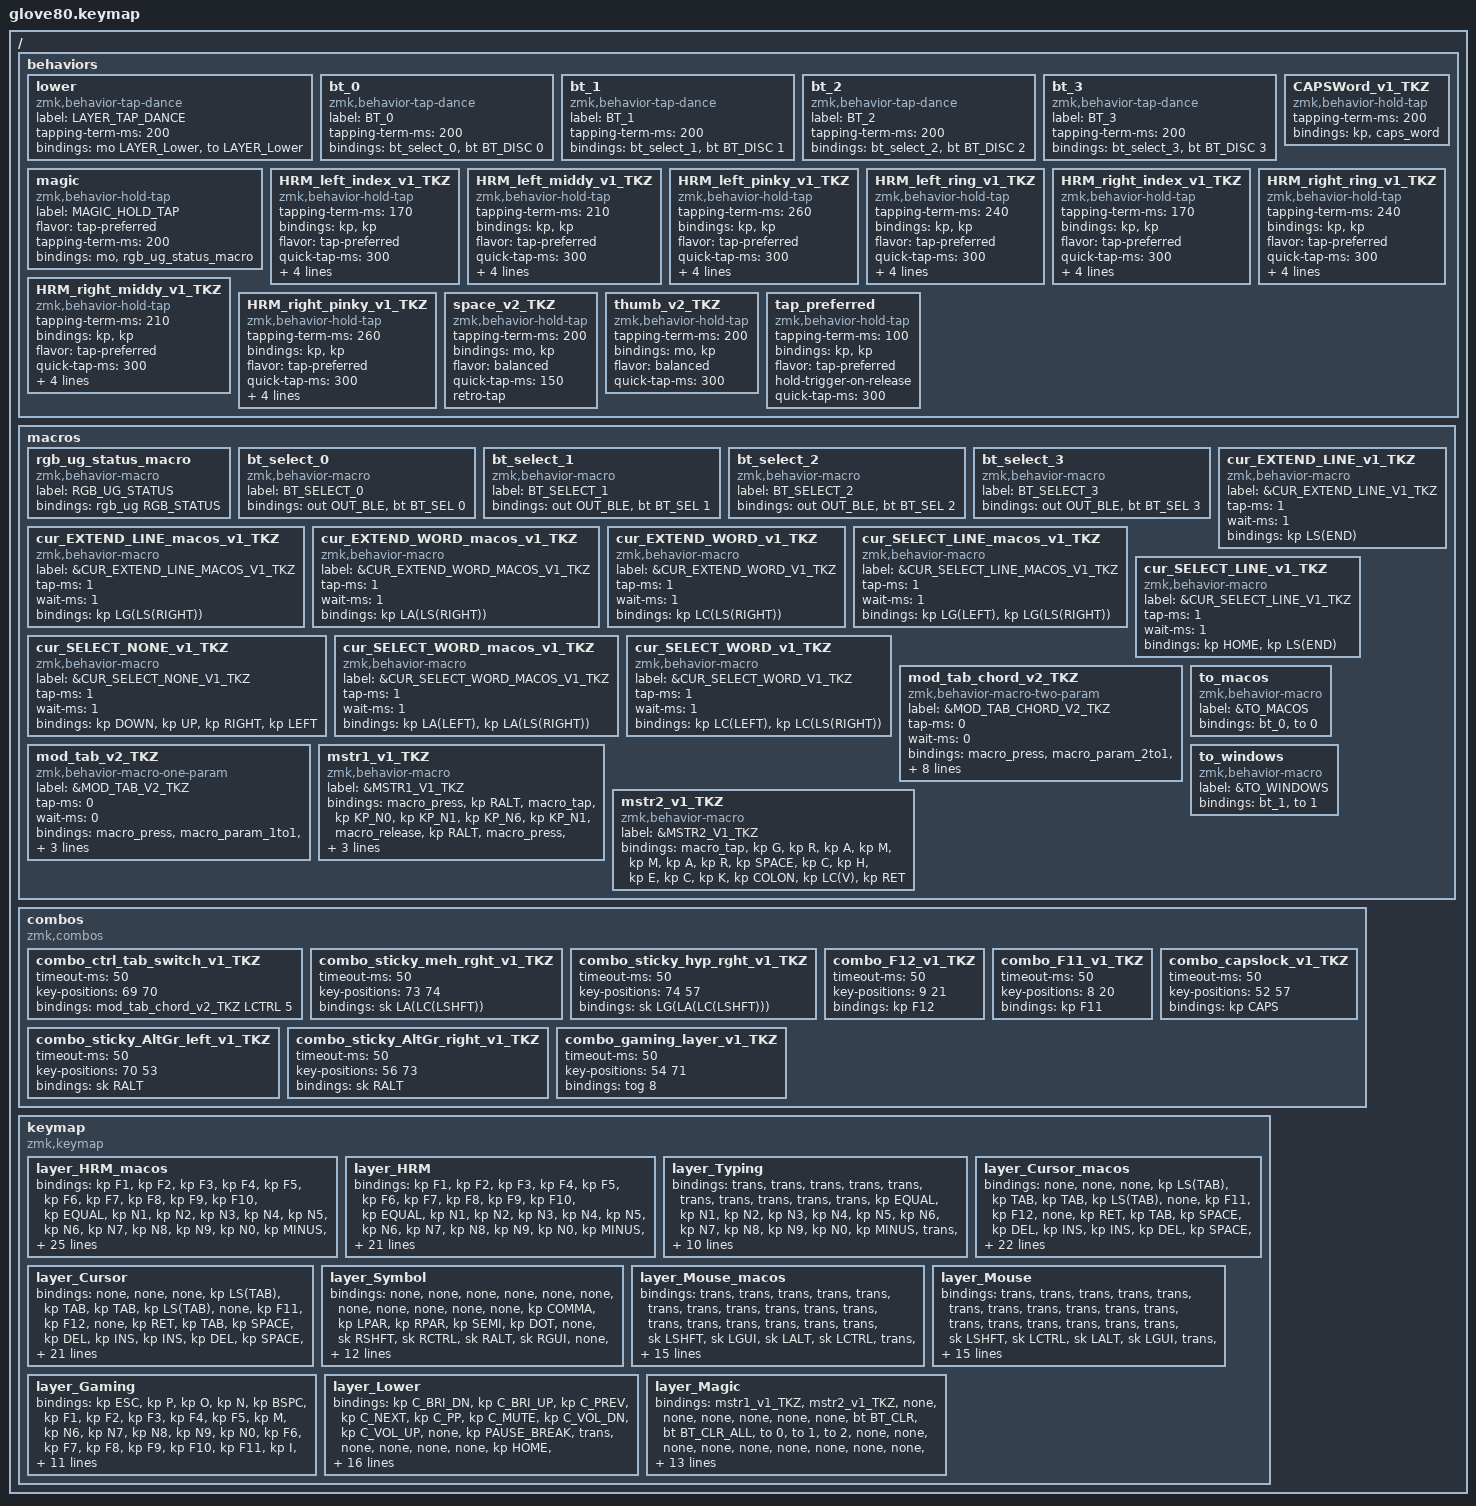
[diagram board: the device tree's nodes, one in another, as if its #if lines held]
/*
 * Copyright (c) 2020 The ZMK Contributors
 * Copyright (c) 2023 Innaworks Development Limited, trading as MoErgo
 *
 * SPDX-License-Identifier: MIT
 */
// clang-format off
/* THIS FILE WAS GENERATED BY GLOVE80 LAYOUT EDITOR
 *
 * This file was generated automatically. You may or may not want to
 * edit it directly.
 */
/* Include all behavior includes needed */
/* On demand includes */

#include <behaviors.dtsi>
#include <dt-bindings/zmk/bt.h>
#include <dt-bindings/zmk/keys.h>
#include <dt-bindings/zmk/outputs.h>
#include <dt-bindings/zmk/pointing.h>
#include <dt-bindings/zmk/rgb.h>

/* */

#define HYPER LC(LS(LG(LALT)))
#define MEH LC(LG(LALT))

/* Automatically generated layer name #define */

#define LAYER_HRM_macos 0
#define LAYER_HRM 1
#define LAYER_Typing 2
#define LAYER_Cursor_macos 3
#define LAYER_Cursor 4
#define LAYER_Symbol 5
#define LAYER_Mouse_macos 6
#define LAYER_Mouse 7
#define LAYER_Gaming 8
#define LAYER_Lower 9
#define LAYER_Magic 10

/* To deal with the situation where there is no Lower layer, to keep &lower happy */
/*#ifndef LAYER_Lower
#define LAYER_Lower 0
#endif
*/
/* Custom Device-tree */
/* Glove80 system behavior & macros */

/ {
    behaviors {
        // For the "layer" key, it'd nice to be able to use it as either a shift or a toggle.
        // Configure it as a tap dance, so the first tap (or hold) is a &mo and the second tap is a &to

        lower: lower {
            compatible = "zmk,behavior-tap-dance";
            label = "LAYER_TAP_DANCE";
            #binding-cells = <0>;
            tapping-term-ms = <200>;
            bindings = <&mo LAYER_Lower>, <&to LAYER_Lower>;
        };
    };
};

/ {
    macros {
        rgb_ug_status_macro: rgb_ug_status_macro {
            label = "RGB_UG_STATUS";
            compatible = "zmk,behavior-macro";
            #binding-cells = <0>;
            bindings = <&rgb_ug RGB_STATUS>;
        };
    };
};

/ {
    #ifdef BT_DISC_CMD

    behaviors {
        bt_0: bt_0 {
            compatible = "zmk,behavior-tap-dance";
            label = "BT_0";
            #binding-cells = <0>;
            tapping-term-ms = <200>;
            bindings = <&bt_select_0>, <&bt BT_DISC 0>;
        };

        bt_1: bt_1 {
            compatible = "zmk,behavior-tap-dance";
            label = "BT_1";
            #binding-cells = <0>;
            tapping-term-ms = <200>;
            bindings = <&bt_select_1>, <&bt BT_DISC 1>;
        };

        bt_2: bt_2 {
            compatible = "zmk,behavior-tap-dance";
            label = "BT_2";
            #binding-cells = <0>;
            tapping-term-ms = <200>;
            bindings = <&bt_select_2>, <&bt BT_DISC 2>;
        };

        bt_3: bt_3 {
            compatible = "zmk,behavior-tap-dance";
            label = "BT_3";
            #binding-cells = <0>;
            tapping-term-ms = <200>;
            bindings = <&bt_select_3>, <&bt BT_DISC 3>;
        };
    };

    macros {
        bt_select_0: bt_select_0 {
            label = "BT_SELECT_0";
            compatible = "zmk,behavior-macro";
            #binding-cells = <0>;
            bindings = <&out OUT_BLE &bt BT_SEL 0>;
        };

        bt_select_1: bt_select_1 {
            label = "BT_SELECT_1";
            compatible = "zmk,behavior-macro";
            #binding-cells = <0>;
            bindings = <&out OUT_BLE &bt BT_SEL 1>;
        };

        bt_select_2: bt_select_2 {
            label = "BT_SELECT_2";
            compatible = "zmk,behavior-macro";
            #binding-cells = <0>;
            bindings = <&out OUT_BLE &bt BT_SEL 2>;
        };

        bt_select_3: bt_select_3 {
            label = "BT_SELECT_3";
            compatible = "zmk,behavior-macro";
            #binding-cells = <0>;
            bindings = <&out OUT_BLE &bt BT_SEL 3>;
        };
    };

    #else

    macros {
        bt_0: bt_0 {
            label = "BT_0";
            compatible = "zmk,behavior-macro";
            #binding-cells = <0>;
            bindings = <&out OUT_BLE &bt BT_SEL 0>;
        };

        bt_1: bt_1 {
            label = "BT_1";
            compatible = "zmk,behavior-macro";
            #binding-cells = <0>;
            bindings = <&out OUT_BLE &bt BT_SEL 1>;
        };

        bt_2: bt_2 {
            label = "BT_2";
            compatible = "zmk,behavior-macro";
            #binding-cells = <0>;
            bindings = <&out OUT_BLE &bt BT_SEL 2>;
        };

        bt_3: bt_3 {
            label = "BT_3";
            compatible = "zmk,behavior-macro";
            #binding-cells = <0>;
            bindings = <&out OUT_BLE &bt BT_SEL 3>;
        };
    };

    #endif
};

/ {
    behaviors {
        magic: magic {
            compatible = "zmk,behavior-hold-tap";
            label = "MAGIC_HOLD_TAP";
            #binding-cells = <2>;
            flavor = "tap-preferred";
            tapping-term-ms = <200>;
            bindings = <&mo>, <&rgb_ug_status_macro>;
        };
    };
};

/* #define for key positions */

#define POS_LH_T1 52
#define POS_LH_T2 53
#define POS_LH_T3 54
#define POS_LH_T4 69
#define POS_LH_T5 70
#define POS_LH_T6 71
#define POS_LH_C1R2 15
#define POS_LH_C1R3 27
#define POS_LH_C1R4 39
#define POS_LH_C1R5 51
#define POS_LH_C2R1 4
#define POS_LH_C2R2 14
#define POS_LH_C2R3 26
#define POS_LH_C2R4 38
#define POS_LH_C2R5 50
#define POS_LH_C2R6 68
#define POS_LH_C3R1 3
#define POS_LH_C3R2 13
#define POS_LH_C3R3 25
#define POS_LH_C3R4 37
#define POS_LH_C3R5 49
#define POS_LH_C3R6 67
#define POS_LH_C4R1 2
#define POS_LH_C4R2 12
#define POS_LH_C4R3 24
#define POS_LH_C4R4 36
#define POS_LH_C4R5 48
#define POS_LH_C4R6 66
#define POS_LH_C5R1 1
#define POS_LH_C5R2 11
#define POS_LH_C5R3 23
#define POS_LH_C5R4 35
#define POS_LH_C5R5 47
#define POS_LH_C5R6 65
#define POS_LH_C6R1 0
#define POS_LH_C6R2 10
#define POS_LH_C6R3 22
#define POS_LH_C6R4 34
#define POS_LH_C6R5 46
#define POS_LH_C6R6 64
#define POS_RH_T1 57
#define POS_RH_T2 56
#define POS_RH_T3 55
#define POS_RH_T4 74
#define POS_RH_T5 73
#define POS_RH_T6 72
#define POS_RH_C1R2 16
#define POS_RH_C1R3 28
#define POS_RH_C1R4 40
#define POS_RH_C1R5 58
#define POS_RH_C2R1 5
#define POS_RH_C2R2 17
#define POS_RH_C2R3 29
#define POS_RH_C2R4 41
#define POS_RH_C2R5 59
#define POS_RH_C2R6 75
#define POS_RH_C3R1 6
#define POS_RH_C3R2 18
#define POS_RH_C3R3 30
#define POS_RH_C3R4 42
#define POS_RH_C3R5 60
#define POS_RH_C3R6 76
#define POS_RH_C4R1 7
#define POS_RH_C4R2 19
#define POS_RH_C4R3 31
#define POS_RH_C4R4 43
#define POS_RH_C4R5 61
#define POS_RH_C4R6 77
#define POS_RH_C5R1 8
#define POS_RH_C5R2 20
#define POS_RH_C5R3 32
#define POS_RH_C5R4 44
#define POS_RH_C5R5 62
#define POS_RH_C5R6 78
#define POS_RH_C6R1 9
#define POS_RH_C6R2 21
#define POS_RH_C6R3 33
#define POS_RH_C6R4 45
#define POS_RH_C6R5 63
#define POS_RH_C6R6 79

/* Custom Defined Behaviors */

/ {
};

/* Automatically generated macro definitions */

/ {
    macros {
        // Cursor Layer - Extent Line (seq) - TailorKey

        cur_EXTEND_LINE_macos_v1_TKZ: cur_EXTEND_LINE_macos_v1_TKZ {
            label = "&CUR_EXTEND_LINE_MACOS_V1_TKZ";
            compatible = "zmk,behavior-macro";
            #binding-cells = <0>;
            tap-ms = <1>;
            wait-ms = <1>;
            bindings = <&kp LG(LS(RIGHT))>;
        };

        // Cursor Layer - Extent Line (seq) - TailorKey

        cur_EXTEND_LINE_v1_TKZ: cur_EXTEND_LINE_v1_TKZ {
            label = "&CUR_EXTEND_LINE_V1_TKZ";
            compatible = "zmk,behavior-macro";
            #binding-cells = <0>;
            tap-ms = <1>;
            wait-ms = <1>;
            bindings = <&kp LS(END)>;
        };

        // Cursor Layer - Extend Word (seq) - TailorKey

        cur_EXTEND_WORD_macos_v1_TKZ: cur_EXTEND_WORD_macos_v1_TKZ {
            label = "&CUR_EXTEND_WORD_MACOS_V1_TKZ";
            compatible = "zmk,behavior-macro";
            #binding-cells = <0>;
            tap-ms = <1>;
            wait-ms = <1>;
            bindings = <&kp LA(LS(RIGHT))>;
        };

        // Cursor Layer - Extend Word (seq) - TailorKey

        cur_EXTEND_WORD_v1_TKZ: cur_EXTEND_WORD_v1_TKZ {
            label = "&CUR_EXTEND_WORD_V1_TKZ";
            compatible = "zmk,behavior-macro";
            #binding-cells = <0>;
            tap-ms = <1>;
            wait-ms = <1>;
            bindings = <&kp LC(LS(RIGHT))>;
        };

        // Cursor Layer macos - Select Line (seq) - TailorKey

        cur_SELECT_LINE_macos_v1_TKZ: cur_SELECT_LINE_macos_v1_TKZ {
            label = "&CUR_SELECT_LINE_MACOS_V1_TKZ";
            compatible = "zmk,behavior-macro";
            #binding-cells = <0>;
            tap-ms = <1>;
            wait-ms = <1>;
            bindings = <&kp LG(LEFT) &kp LG(LS(RIGHT))>;
        };

        // Cursor Layer - Select Line (seq) - TailorKey

        cur_SELECT_LINE_v1_TKZ: cur_SELECT_LINE_v1_TKZ {
            label = "&CUR_SELECT_LINE_V1_TKZ";
            compatible = "zmk,behavior-macro";
            #binding-cells = <0>;
            tap-ms = <1>;
            wait-ms = <1>;
            bindings = <&kp HOME &kp LS(END)>;
        };

        // Cursor Layer - Select None (seq) - TailorKey

        cur_SELECT_NONE_v1_TKZ: cur_SELECT_NONE_v1_TKZ {
            label = "&CUR_SELECT_NONE_V1_TKZ";
            compatible = "zmk,behavior-macro";
            #binding-cells = <0>;
            tap-ms = <1>;
            wait-ms = <1>;
            bindings = <&kp DOWN &kp UP &kp RIGHT &kp LEFT>;
        };

        // Cursor Layer - Select Word (seq) - TailorKey

        cur_SELECT_WORD_macos_v1_TKZ: cur_SELECT_WORD_macos_v1_TKZ {
            label = "&CUR_SELECT_WORD_MACOS_V1_TKZ";
            compatible = "zmk,behavior-macro";
            #binding-cells = <0>;
            tap-ms = <1>;
            wait-ms = <1>;
            bindings = <&kp LA(LEFT) &kp LA(LS(RIGHT))>;
        };

        // Cursor Layer - Select Word (seq) - TailorKey

        cur_SELECT_WORD_v1_TKZ: cur_SELECT_WORD_v1_TKZ {
            label = "&CUR_SELECT_WORD_V1_TKZ";
            compatible = "zmk,behavior-macro";
            #binding-cells = <0>;
            tap-ms = <1>;
            wait-ms = <1>;
            bindings = <&kp LC(LEFT) &kp LC(LS(RIGHT))>;
        };

        // mod_tab_switcher_chord -  TailorKey

        mod_tab_chord_v2_TKZ: mod_tab_chord_v2_TKZ {
            label = "&MOD_TAB_CHORD_V2_TKZ";
            compatible = "zmk,behavior-macro-two-param";
            #binding-cells = <2>;
            tap-ms = <0>;
            wait-ms = <0>;
            bindings =
                <&macro_press>,
                <&macro_param_2to1 &mo MACRO_PLACEHOLDER>,
                <&macro_press>,
                <&macro_param_1to1 &mod_tab_v2_TKZ MACRO_PLACEHOLDER>,
                <&macro_pause_for_release>,
                <&macro_release>,
                <&macro_param_1to1 &mod_tab_v2_TKZ MACRO_PLACEHOLDER>,
                <&macro_release>,
                <&macro_param_2to1 &mo MACRO_PLACEHOLDER>;
        };

        // mod_tab_switcher - TailorKey
        // 
        // 

        mod_tab_v2_TKZ: mod_tab_v2_TKZ {
            label = "&MOD_TAB_V2_TKZ";
            compatible = "zmk,behavior-macro-one-param";
            #binding-cells = <1>;
            tap-ms = <0>;
            wait-ms = <0>;
            bindings =
                <&macro_press>,
                <&macro_param_1to1 &kp MACRO_PLACEHOLDER>,
                <&macro_tap>,
                <&kp TAB>,
                <&macro_pause_for_release>,
                <&macro_release>,
                <&macro_param_1to1 &kp MACRO_PLACEHOLDER>;
        };

        // macro string1 sample - Magic Layer F1 - Text output sample macro 1 "¡Hola!" - TailorKey

        mstr1_v1_TKZ: mstr1_v1_TKZ {
            label = "&MSTR1_V1_TKZ";
            compatible = "zmk,behavior-macro";
            #binding-cells = <0>;
            bindings =
                <&macro_press>,
                <&kp RALT>,
                <&macro_tap>,
                <&kp KP_N0 &kp KP_N1 &kp KP_N6 &kp KP_N1>,
                <&macro_release>,
                <&kp RALT>,
                <&macro_press>,
                <&kp LSHFT>,
                <&macro_tap>,
                <&kp H>,
                <&macro_release>,
                <&kp LSHFT>,
                <&macro_tap>,
                <&kp O &kp L &kp A &kp EXCL &kp SPACE &kp RET>;
        };

        // macro string2 sample - Magic Layer F2 - Text output sample macro 2 "grammar check: <paste>" - TailorKey

        mstr2_v1_TKZ: mstr2_v1_TKZ {
            label = "&MSTR2_V1_TKZ";
            compatible = "zmk,behavior-macro";
            #binding-cells = <0>;
            bindings =
                <&macro_tap>,
                <&kp G &kp R &kp A &kp M &kp M &kp A &kp R &kp SPACE &kp C &kp H &kp E &kp C &kp K &kp COLON &kp LC(V) &kp RET>;
        };

        // macos keybinds and bt

        to_macos: to_macos {
            label = "&TO_MACOS";
            compatible = "zmk,behavior-macro";
            #binding-cells = <0>;
            bindings = <&bt_0 &to 0>;
        };

        // windows keybinds and bt uses bt1 and layer 1

        to_windows: to_windows {
            label = "&TO_WINDOWS";
            compatible = "zmk,behavior-macro";
            #binding-cells = <0>;
            bindings = <&bt_1 &to 1>;
        };
    };
};

/* Automatically generated behavior definitions */

/ {
    behaviors {
        // Capsword helper - tap for caps_word - hold for key press

        CAPSWord_v1_TKZ: CAPSWord_v1_TKZ {
            compatible = "zmk,behavior-hold-tap";
            #binding-cells = <2>;
            tapping-term-ms = <200>;
            bindings = <&kp>, <&caps_word>;
        };

        // Homerow Mod for the left index finger - TailorKey.
        // For advanced tuning of HRM values, see: https://docs.google.com/spreadsheets/d/1ESgObQelyz4lnKlfwLYsmofLJulOMK5RdGBsopLe2o8

        HRM_left_index_v1_TKZ: HRM_left_index_v1_TKZ {
            compatible = "zmk,behavior-hold-tap";
            #binding-cells = <2>;
            tapping-term-ms = <170>;
            bindings = <&kp>, <&kp>;

            flavor = "tap-preferred";
            quick-tap-ms = <300>;
            require-prior-idle-ms = <100>;
            hold-trigger-key-positions = <57 56 55 72 73 74 5 6 7 8 16 17 18 19 20 28 29 30 31 32 40 41 42 43 44 58 59 60 61 62 75 76 77 78 9 21 33 45 63 79 52 53 54 70 71 69>;
            hold-trigger-on-release;
        };

        // Homerow Mod for the left middle finger - TailorKey

        HRM_left_middy_v1_TKZ: HRM_left_middy_v1_TKZ {
            compatible = "zmk,behavior-hold-tap";
            #binding-cells = <2>;
            tapping-term-ms = <210>;
            bindings = <&kp>, <&kp>;

            flavor = "tap-preferred";
            quick-tap-ms = <300>;
            require-prior-idle-ms = <150>;
            hold-trigger-key-positions = <57 56 55 72 73 74 5 6 7 8 16 17 18 19 20 28 29 30 31 32 40 41 42 43 44 58 59 60 61 62 75 76 77 78 9 21 33 45 63 79 52 53 54 69 70 71>;
            hold-trigger-on-release;
        };

        // Homerow Mod for the left pinky - TailorKey

        HRM_left_pinky_v1_TKZ: HRM_left_pinky_v1_TKZ {
            compatible = "zmk,behavior-hold-tap";
            #binding-cells = <2>;
            tapping-term-ms = <260>;
            bindings = <&kp>, <&kp>;

            flavor = "tap-preferred";
            quick-tap-ms = <300>;
            require-prior-idle-ms = <150>;
            hold-trigger-key-positions = <57 56 55 72 73 74 5 6 7 8 9 16 17 18 19 20 21 29 30 31 32 33 42 43 44 45 60 61 62 63 28 40 41 58 59 75 76 77 79 78 52 53 54 69 70 71>;
            hold-trigger-on-release;
        };

        // Homerow Mod for the left ring finger 1 - TailorKey

        HRM_left_ring_v1_TKZ: HRM_left_ring_v1_TKZ {
            compatible = "zmk,behavior-hold-tap";
            #binding-cells = <2>;
            tapping-term-ms = <240>;
            bindings = <&kp>, <&kp>;

            flavor = "tap-preferred";
            quick-tap-ms = <300>;
            require-prior-idle-ms = <150>;
            hold-trigger-key-positions = <57 56 55 72 73 74 5 6 7 8 16 17 18 19 20 28 29 30 31 32 40 41 42 43 44 58 59 60 61 62 75 76 77 78 9 21 33 45 63 79 52 53 54 69 70 71>;
            hold-trigger-on-release;
        };

        // Homerow Mod for the right index finger - TailorKey

        HRM_right_index_v1_TKZ: HRM_right_index_v1_TKZ {
            compatible = "zmk,behavior-hold-tap";
            #binding-cells = <2>;
            tapping-term-ms = <170>;
            bindings = <&kp>, <&kp>;

            flavor = "tap-preferred";
            quick-tap-ms = <300>;
            require-prior-idle-ms = <100>;
            hold-trigger-key-positions = <52 53 54 71 70 69 0 1 10 11 12 13 14 22 23 24 25 26 27 34 35 36 37 38 39 46 47 48 49 50 51 64 65 66 67 68 15 4 2 3 55 56 57 72 73 74>;
            hold-trigger-on-release;
        };

        // Homerow Mod for the right middle finger - TailorKey

        HRM_right_middy_v1_TKZ: HRM_right_middy_v1_TKZ {
            compatible = "zmk,behavior-hold-tap";
            #binding-cells = <2>;
            tapping-term-ms = <210>;
            bindings = <&kp>, <&kp>;

            flavor = "tap-preferred";
            quick-tap-ms = <300>;
            require-prior-idle-ms = <150>;
            hold-trigger-key-positions = <52 53 54 71 70 69 0 1 10 11 12 13 14 22 23 24 25 26 27 34 35 36 37 38 39 46 47 48 49 50 51 64 65 66 67 68 15 4 2 3 55 56 57 72 73 74>;
            hold-trigger-on-release;
        };

        // Homerow Mod for the right pinky - TailorKey

        HRM_right_pinky_v1_TKZ: HRM_right_pinky_v1_TKZ {
            compatible = "zmk,behavior-hold-tap";
            #binding-cells = <2>;
            tapping-term-ms = <260>;
            bindings = <&kp>, <&kp>;

            flavor = "tap-preferred";
            quick-tap-ms = <300>;
            require-prior-idle-ms = <150>;
            hold-trigger-key-positions = <52 53 54 71 70 69 0 1 10 11 12 13 14 22 23 24 25 26 27 34 35 36 37 38 39 46 47 48 49 50 51 64 65 66 67 68 15 4 2 3 55 56 57 72 73 74>;
            hold-trigger-on-release;
        };

        // Homerow Mod for the right ring 1 - TailorKey
        // 

        HRM_right_ring_v1_TKZ: HRM_right_ring_v1_TKZ {
            compatible = "zmk,behavior-hold-tap";
            #binding-cells = <2>;
            tapping-term-ms = <240>;
            bindings = <&kp>, <&kp>;

            flavor = "tap-preferred";
            quick-tap-ms = <300>;
            require-prior-idle-ms = <150>;
            hold-trigger-key-positions = <52 53 54 71 70 69 0 1 10 11 12 13 14 22 23 24 25 26 27 34 35 36 37 38 39 46 47 48 49 50 51 64 65 66 67 68 15 4 2 3 55 56 57 72 73 74>;
            hold-trigger-on-release;
        };

        // space_layer_access - TailorKey

        space_v2_TKZ: space_v2_TKZ {
            compatible = "zmk,behavior-hold-tap";
            #binding-cells = <2>;
            tapping-term-ms = <200>;
            bindings = <&mo>, <&kp>;

            flavor = "balanced";
            quick-tap-ms = <150>;
            retro-tap;
        };

        // thumb_layer_access - TailorKey

        thumb_v2_TKZ: thumb_v2_TKZ {
            compatible = "zmk,behavior-hold-tap";
            #binding-cells = <2>;
            tapping-term-ms = <200>;
            bindings = <&mo>, <&kp>;

            flavor = "balanced";
            quick-tap-ms = <300>;
        };

        // prefer tap instead of modifier

        tap_preferred: tap_preferred {
            compatible = "zmk,behavior-hold-tap";
            #binding-cells = <2>;
            tapping-term-ms = <100>;
            bindings = <&kp>, <&kp>;

            flavor = "tap-preferred";
            hold-trigger-on-release;
            quick-tap-ms = <300>;
        };
    };
};

/* Automatically generated combos definitions */

/ {
    combos {
        compatible = "zmk,combos";

        // Calls macro tab_switcher_ctrl_combo on Left T4/T5 - TailorKey

        combo_ctrl_tab_switch_v1_TKZ {
            timeout-ms = <50>;
            key-positions = <69 70>;
            bindings = <&mod_tab_chord_v2_TKZ LCTRL 5>;
        };

        // sticky "meh" modifiers (Alt + Ctrl + Shift) - TailorKey

        combo_sticky_meh_rght_v1_TKZ {
            timeout-ms = <50>;
            key-positions = <73 74>;
            bindings = <&sk LA(LC(LSHFT))>;
        };

        // sticky "hyper" modifiers (Win + Alt + Ctrl + Shift) - TailorKey

        combo_sticky_hyp_rght_v1_TKZ {
            timeout-ms = <50>;
            key-positions = <74 57>;
            bindings = <&sk LG(LA(LC(LSHFT)))>;
        };

        // F12 on RH_C6 and RH_R1+R2 - TailorKey

        combo_F12_v1_TKZ {
            timeout-ms = <50>;
            key-positions = <9 21>;
            bindings = <&kp F12>;
        };

        // F11 on RH_C5 and RH_R1+R2 - TailorKey

        combo_F11_v1_TKZ {
            timeout-ms = <50>;
            key-positions = <8 20>;
            bindings = <&kp F11>;
        };

        // capslock when pressing both T1's - TailorKey

        combo_capslock_v1_TKZ {
            timeout-ms = <50>;
            key-positions = <52 57>;
            bindings = <&kp CAPS>;
        };

        // sticky "AltGr" left - TailorKey

        combo_sticky_AltGr_left_v1_TKZ {
            timeout-ms = <50>;
            key-positions = <70 53>;
            bindings = <&sk RALT>;
        };

        // sticky "AltGr" right - TailorKey

        combo_sticky_AltGr_right_v1_TKZ {
            timeout-ms = <50>;
            key-positions = <56 73>;
            bindings = <&sk RALT>;
        };

        // toggle gaming layer - TailorKey

        combo_gaming_layer_v1_TKZ {
            timeout-ms = <50>;
            key-positions = <54 71>;
            bindings = <&tog 8>;
        };
    };
};

/* Automatically generated keymap */

/ {
    keymap {
        compatible = "zmk,keymap";

        layer_HRM_macos {
            bindings = <
&kp F1                                        &kp F2                              &kp F3                        &kp F4                         &kp F5                                                                                                                                                                 &kp F6                           &kp F7                          &kp F8                         &kp F9                              &kp F10
&kp EQUAL                                     &kp N1                              &kp N2                        &kp N3                         &kp N4                          &kp N5                                                                                                                         &kp N6  &kp N7                           &kp N8                          &kp N9                         &kp N0                              &kp MINUS
&HRM_left_pinky_v1_TKZ LS(LC(LALT)) TAB       &kp Q                               &kp W                         &kp E                          &kp R                           &kp T                                                                                                                          &kp Y   &kp U                            &kp I                           &kp O                          &kp P                               &HRM_right_pinky_v1_TKZ LS(LC(LALT)) BSLH
&HRM_left_pinky_v1_TKZ LG(LC(LA(LSHFT))) ESC  &HRM_left_pinky_v1_TKZ LC(LSHFT) A  &HRM_left_ring_v1_TKZ LGUI S  &HRM_left_middy_v1_TKZ LALT D  &HRM_left_index_v1_TKZ LSHFT F  &kp G                                                                                                                          &kp H   &HRM_right_index_v1_TKZ RSHFT J  &HRM_right_middy_v1_TKZ RALT K  &HRM_right_ring_v1_TKZ RGUI L  &HRM_right_pinky_v1_TKZ RCTRL SEMI  &HRM_right_pinky_v1_TKZ LG(LC(LS(LALT))) SQT
&mt LSHFT GRAVE                               &kp Z                               &kp X                         &kp C                          &kp V                           &kp B   &kp F19               &kp LS(MINUS)  &lower   &kp HOME  &kp RGUI             &CAPSWord_v1_TKZ RSHFT MACRO_PLACEHOLDER  &kp N   &kp M                            &kp COMMA                       &kp DOT                        &kp FSLH                            &kp PG_UP
&magic LAYER_Magic 0                          &kp GRAVE                           &kp F24                       &kp LEFT                       &kp RIGHT                               &thumb_v2_TKZ 3 BSPC  &mt LCTRL F17  &kp F18  &kp END   &thumb_v2_TKZ 6 RET  &space_v2_TKZ 5 SPACE                             &kp UP                           &kp DOWN                        &kp LBKT                       &kp RBKT                            &kp PG_DN
            >;
        };

        layer_HRM {
            bindings = <
&kp F1                &kp F2                         &kp F3                         &kp F4                         &kp F5                                                                                                                                                                        &kp F6                           &kp F7                          &kp F8                          &kp F9                             &kp F10
&kp EQUAL             &kp N1                         &kp N2                         &kp N3                         &kp N4                          &kp N5                                                                                                                                &kp N6  &kp N7                           &kp N8                          &kp N9                          &kp N0                             &kp MINUS
&kp TAB               &kp Q                          &kp W                          &kp E                          &kp R                           &kp T                                                                                                                                 &kp Y   &kp U                            &kp I                           &kp O                           &kp P                              &kp BSLH
&kp ESC               &HRM_left_pinky_v1_TKZ LGUI A  &HRM_left_ring_v1_TKZ LCTRL S  &HRM_left_middy_v1_TKZ LALT D  &HRM_left_index_v1_TKZ LSHFT F  &kp G                                                                                                                                 &kp H   &HRM_right_index_v1_TKZ RSHFT J  &HRM_right_middy_v1_TKZ LALT K  &HRM_right_ring_v1_TKZ RCTRL L  &HRM_right_pinky_v1_TKZ LGUI SEMI  &kp SQT
&mt LSHFT GRAVE       &kp Z                          &kp X                          &kp C                          &kp V                           &kp B   &kp F19               &kp LCTRL      &lower   &kp DELETE       &kp RCTRL            &CAPSWord_v1_TKZ RSHFT MACRO_PLACEHOLDER  &kp N   &kp M                            &kp COMMA                       &kp DOT                         &kp FSLH                           &kp PG_UP
&magic LAYER_Magic 0  &kp HOME                       &kp END                        &kp LEFT                       &kp RIGHT                               &thumb_v2_TKZ 4 BSPC  &mt LCTRL F17  &kp END  &kp PRINTSCREEN  &thumb_v2_TKZ 7 RET  &space_v2_TKZ 5 SPACE                             &kp UP                           &kp DOWN                        &kp LBKT                        &kp RBKT                           &kp PG_DN
            >;
        };

        layer_Typing {
            bindings = <
&trans                &trans  &trans  &trans  &trans                                                                  &trans  &trans     &trans    &trans    &trans
&kp EQUAL             &kp N1  &kp N2  &kp N3  &kp N4  &kp N5                                                  &kp N6  &kp N7  &kp N8     &kp N9    &kp N0    &kp MINUS
&trans                &kp Q   &kp W   &kp E   &kp R   &kp T                                                   &kp Y   &kp U   &kp I      &kp O     &kp P     &kp BSLH
&trans                &kp A   &kp S   &kp D   &kp F   &kp G                                                   &kp H   &kp J   &kp K      &kp L     &kp SEMI  &kp SQT
&kp GRAVE             &kp Z   &kp X   &kp C   &kp V   &kp B   &trans  &trans  &trans  &trans  &trans  &trans  &kp N   &kp M   &kp COMMA  &kp DOT   &kp FSLH  &trans
&magic LAYER_Magic 0  &trans  &trans  &trans  &trans          &trans  &trans  &trans  &trans  &trans  &trans          &trans  &trans     &kp LBKT  &kp RBKT  &trans
            >;
        };

        layer_Cursor_macos {
            bindings = <
&none      &none          &none                          &kp LS(TAB)                    &kp TAB                                                                                                                                                                          &kp TAB    &kp LS(TAB)    &none          &kp F11    &kp F12
&none      &kp RET        &kp TAB                        &kp SPACE                      &kp DEL    &kp INS                                                                                                                                                    &kp INS    &kp DEL    &kp SPACE      &kp TAB        &kp RET    &none
&none      &kp ESC        &kp LG(LS(Z))                  &kp LG(Z)                      &kp BSPC   &kp LG(X)                                                                                                                                                  &kp LG(X)  &kp BSPC   &kp LG(Z)      &kp LG(LS(Z))  &kp ESC    &none
&sk LSHFT  &kp LCTRL      &kp LALT                       &kp LGUI                       &kp LSHFT  &kp LG(C)                                                                                                                                                  &kp LEFT   &kp DOWN   &kp UP         &kp RIGHT      &kp LG(C)  &sk RSHFT
&kp LG(L)  &kp LG(A)      &cur_SELECT_LINE_macos_v1_TKZ  &cur_SELECT_WORD_macos_v1_TKZ  &kp LG(F)  &kp LG(V)  &mod_tab_v2_TKZ LGUI  &mod_tab_v2_TKZ LALT   &kp PSCRN   &cur_SELECT_NONE_v1_TKZ  &cur_EXTEND_LINE_macos_v1_TKZ  &cur_EXTEND_WORD_macos_v1_TKZ  &kp LG(V)  &kp HOME   &kp PG_UP      &kp PG_DN      &kp END    &kp LG(L)
&kp LG(K)  &kp LG(LS(G))  &cur_EXTEND_LINE_macos_v1_TKZ  &cur_EXTEND_WORD_macos_v1_TKZ  &kp LG(G)             &none                 &mod_tab_v2_TKZ LCTRL  &kp LG(F3)  &kp LG(A)                &cur_SELECT_LINE_macos_v1_TKZ  &cur_SELECT_WORD_macos_v1_TKZ             &kp LG(F)  &kp LG(LS(G))  &kp LG(G)      &kp LC(H)  &kp LG(K)
            >;
        };

        layer_Cursor {
            bindings = <
&none      &none          &none                    &kp LS(TAB)              &kp TAB                                                                                                                                                             &kp TAB    &kp LS(TAB)    &none      &kp F11    &kp F12
&none      &kp RET        &kp TAB                  &kp SPACE                &kp DEL    &kp INS                                                                                                                                       &kp INS    &kp DEL    &kp SPACE      &kp TAB    &kp RET    &none
&none      &kp ESC        &kp LC(Y)                &kp LC(Z)                &kp BSPC   &kp LC(X)                                                                                                                                     &kp LC(X)  &kp BSPC   &kp LC(Z)      &kp LC(Y)  &kp ESC    &none
&sk LSHFT  &kp LGUI       &kp LALT                 &kp LCTRL                &kp LSHFT  &kp LC(C)                                                                                                                                     &kp LEFT   &kp DOWN   &kp UP         &kp RIGHT  &kp LC(C)  &sk RSHFT
&kp LC(L)  &kp LC(A)      &cur_SELECT_LINE_v1_TKZ  &cur_SELECT_WORD_v1_TKZ  &kp LC(F)  &kp LC(V)  &mod_tab_v2_TKZ LALT  &mod_tab_v2_TKZ LGUI   &kp PSCRN  &cur_SELECT_NONE_v1_TKZ  &cur_EXTEND_LINE_v1_TKZ  &cur_EXTEND_WORD_v1_TKZ  &kp LC(V)  &kp HOME   &kp PG_UP      &kp PG_DN  &kp END    &kp LC(L)
&kp LC(K)  &kp LC(LS(G))  &cur_EXTEND_LINE_v1_TKZ  &cur_EXTEND_WORD_v1_TKZ  &kp LC(G)             &none                 &mod_tab_v2_TKZ LCTRL  &kp LG(D)  &kp LC(A)                &cur_SELECT_LINE_v1_TKZ  &cur_SELECT_WORD_v1_TKZ             &kp LC(F)  &kp LC(LS(G))  &kp LC(G)  &kp LC(H)  &kp LC(K)
            >;
        };

        layer_Symbol {
            bindings = <
&none      &none      &none      &none      &none                                                                                &none      &none      &none        &none      &none
&none      &kp COMMA  &kp LPAR   &kp RPAR   &kp SEMI  &kp DOT                                                         &none      &sk RSHFT  &sk RCTRL  &sk RALT     &sk RGUI   &none
&kp EXCL   &kp LBKT   &kp LBRC   &kp RBRC   &kp RBKT  &kp QMARK                                                       &kp GRAVE  &kp DEL    &kp INS    &kp LS(TAB)  &kp ESC    &none
&kp HASH   &kp CARET  &kp EQUAL  &kp UNDER  &kp DLLR  &kp STAR                                                        &kp DQT    &kp BSPC   &kp SPACE  &kp TAB      &kp RET    &none
&kp TILDE  &kp LT     &kp PIPE   &kp MINUS  &kp GT    &kp FSLH   &kp BSLH   &kp DOT    &kp STAR  &none  &none  &none  &kp SQT    &kp LEFT   &kp UP     &kp DOWN     &kp RIGHT  &none
&kp GRAVE  &kp AMPS   &kp SQT    &kp DQT    &kp PLUS             &kp PRCNT  &kp COLON  &kp AT    &none  &none  &none             &kp HOME   &kp PG_UP  &kp PG_DN    &kp END    &none
            >;
        };

        layer_Mouse_macos {
            bindings = <
&trans  &trans          &trans          &trans          &trans                                                                                         &trans          &trans        &trans          &trans           &trans
&trans  &trans          &trans          &trans          &trans           &trans                                                             &trans     &sk LSHFT       &sk LGUI      &sk LALT        &sk LCTRL        &trans
&trans  &trans          &msc SCRL_LEFT  &mmv MOVE_UP    &msc SCRL_RIGHT  &kp LG(X)                                                          &kp LG(X)  &mkp LCLK       &mkp RCLK     &mkp MCLK       &mkp MB4         &trans
&trans  &msc SCRL_UP    &mmv MOVE_LEFT  &mmv MOVE_DOWN  &mmv MOVE_RIGHT  &kp LG(C)                                                          &kp LG(C)  &none           &none         &none           &mkp MB5         &trans
&trans  &msc SCRL_DOWN  &none           &none           &none            &kp LG(V)  &mkp MCLK  &kp K_APP  &mkp MB5  &trans  &trans  &trans  &kp LG(V)  &mmv MOVE_LEFT  &mmv MOVE_UP  &mmv MOVE_DOWN  &mmv MOVE_RIGHT  &trans
&trans  &trans          &trans          &trans          &trans                      &mkp LCLK  &mkp RCLK  &mkp MB4  &trans  &trans  &trans             &msc SCRL_LEFT  &msc SCRL_UP  &msc SCRL_DOWN  &msc SCRL_RIGHT  &trans
            >;
        };

        layer_Mouse {
            bindings = <
&trans  &trans          &trans          &trans          &trans                                                                                         &trans          &trans        &trans          &trans           &trans
&trans  &trans          &trans          &trans          &trans           &trans                                                             &trans     &sk LSHFT       &sk LCTRL     &sk LALT        &sk LGUI         &trans
&trans  &trans          &msc SCRL_LEFT  &mmv MOVE_UP    &msc SCRL_RIGHT  &kp LC(X)                                                          &kp LC(X)  &mkp LCLK       &mkp RCLK     &mkp MCLK       &mkp MB4         &trans
&trans  &msc SCRL_UP    &mmv MOVE_LEFT  &mmv MOVE_DOWN  &mmv MOVE_RIGHT  &kp LC(C)                                                          &kp LC(C)  &none           &none         &none           &mkp MB5         &trans
&trans  &msc SCRL_DOWN  &none           &none           &none            &kp LC(V)  &mkp MCLK  &kp K_APP  &mkp MB5  &trans  &trans  &trans  &kp LC(V)  &mmv MOVE_LEFT  &mmv MOVE_UP  &mmv MOVE_DOWN  &mmv MOVE_RIGHT  &trans
&trans  &trans          &trans          &trans          &trans                      &mkp LCLK  &mkp RCLK  &mkp MB4  &trans  &trans  &trans             &msc SCRL_LEFT  &msc SCRL_UP  &msc SCRL_DOWN  &msc SCRL_RIGHT  &trans
            >;
        };

        layer_Gaming {
            bindings = <
&kp ESC  &kp P      &kp O   &kp N   &kp BSPC                                                                                &kp F1    &kp F2     &kp F3     &kp F4    &kp F5
&kp M    &kp N6     &kp N7  &kp N8  &kp N9    &kp N0                                                                &kp F6  &kp F7    &kp F8     &kp F9     &kp F10   &kp F11
&kp I    &kp N1     &kp N2  &kp N3  &kp N4    &kp N5                                                                &kp Y   &kp U     &kp I      &kp O      &kp P     &kp F12
&kp T    &kp TAB    &kp Q   &kp W   &kp E     &kp R                                                                 &kp H   &kp J     &kp K      &kp L      &kp SEMI  &kp SQT
&kp G    &kp LSHFT  &kp A   &kp S   &kp D     &kp F   &kp LSHFT  &kp LALT   &kp RET  &kp ESC   &kp UP    &kp RET    &kp N   &kp M     &kp COMMA  &kp DOT    &kp FSLH  &kp BSLH
&kp B    &kp LCTRL  &kp Z   &kp X   &kp C             &kp SPACE  &kp LCTRL  &kp V    &kp LEFT  &kp DOWN  &kp RIGHT          &kp LBKT  &kp MINUS  &kp EQUAL  &kp RBKT  &kp GRAVE
            >;
        };

        layer_Lower {
            bindings = <
&kp C_BRI_DN          &kp C_BRI_UP  &kp C_PREV      &kp C_NEXT      &kp C_PP                                                                                           &kp C_MUTE  &kp C_VOL_DN  &kp C_VOL_UP  &none            &kp PAUSE_BREAK
&trans                &none         &none           &none           &none            &kp HOME                                                   &kp LEFT_PARENTHESIS   &kp KP_NUM  &kp EQUAL     &kp KP_SLASH  &kp KP_MULTIPLY  &kp PRINTSCREEN
&trans                &none         &none           &kp UP_ARROW    &none            &kp END                                                    &kp RIGHT_PARENTHESIS  &kp KP_N7   &kp KP_N8     &kp KP_N9     &kp KP_MINUS     &kp SCROLLLOCK
&trans                &none         &kp LEFT_ARROW  &kp DOWN_ARROW  &kp RIGHT_ARROW  &kp PG_UP                                                  &kp PERCENT            &kp KP_N4   &kp KP_N5     &kp KP_N6     &kp KP_PLUS      &none
&trans                &kp K_APP     &none           &kp F11         &kp F12          &kp PG_DN  &trans  &trans  &to 1   &trans  &trans  &trans  &kp COMMA              &kp KP_N1   &kp KP_N2     &kp KP_N3     &kp KP_ENTER     &trans
&magic LAYER_Magic 0  &kp CAPS      &kp INS         &kp F11         &kp F12                     &trans  &trans  &trans  &trans  &trans  &trans                         &kp KP_N0   &kp KP_N0     &kp KP_DOT    &kp KP_ENTER     &trans
            >;
        };

        layer_Magic {
            bindings = <
&mstr1_v1_TKZ  &mstr2_v1_TKZ    &none            &none            &none                                                                                     &none  &none  &none  &bt BT_CLR  &bt BT_CLR_ALL
&to 0          &to 1            &to 2            &none            &none            &none                                                             &none  &none  &none  &none  &none       &none
&none          &rgb_ug RGB_SPI  &rgb_ug RGB_SAI  &rgb_ug RGB_HUI  &rgb_ug RGB_BRI  &rgb_ug RGB_TOG                                                   &none  &none  &none  &none  &none       &none
&bootloader    &rgb_ug RGB_SPD  &rgb_ug RGB_SAD  &rgb_ug RGB_HUD  &rgb_ug RGB_BRD  &rgb_ug RGB_EFF                                                   &none  &none  &none  &none  &none       &bootloader
&sys_reset     &none            &none            &none            &none            &none            &bt_2  &bt_3  &none         &none  &none  &none  &none  &none  &none  &none  &none       &sys_reset
&none          &none            &none            &to_macos        &to_windows                       &bt_0  &bt_1  &out OUT_USB  &none  &none  &none         &none  &none  &none  &none       &none
            >;
        };
    };
};
